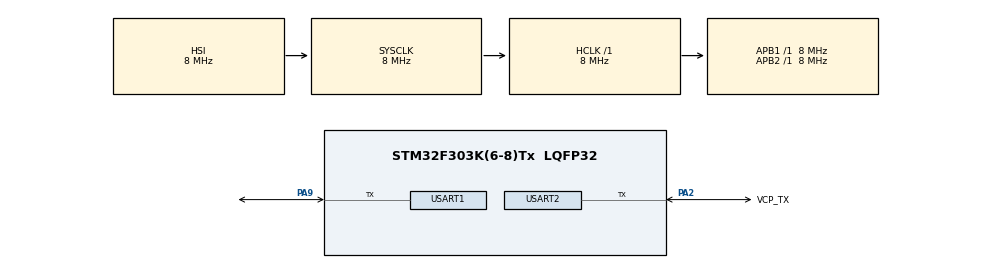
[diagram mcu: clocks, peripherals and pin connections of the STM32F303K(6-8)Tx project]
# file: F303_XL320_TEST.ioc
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Mcu.Family=STM32F3
Mcu.Name=STM32F303K(6-8)Tx
Mcu.Package=LQFP32
NVIC.PriorityGroup=NVIC_PRIORITYGROUP_4
PA13.GPIO_Label=SWDIO
PA13.Mode=Serial_Wire
PA13.Signal=SYS_JTMS-SWDIO
PA14.GPIO_Label=SWCLK
PA14.Mode=Serial_Wire
PA14.Signal=SYS_JTCK-SWCLK
PA15.GPIO_Label=VCP_RX
PA15.Signal=USART2_RX
PA2.GPIO_Label=VCP_TX
PA2.Mode=Half_duplex(single_wire_mode)
PA2.Signal=USART2_TX
PA9.GPIO_ModeDefaultOD=GPIO_MODE_AF_OD
PA9.GPIO_ModeDefaultPP=GPIO_MODE_AF_PP
PA9.GPIO_PuPd=GPIO_NOPULL
PA9.Mode=Half_duplex(single_wire_mode)
PA9.Signal=USART1_TX
PF0\ /\ OSC_IN.GPIO_Label=MCO
PF0\ /\ OSC_IN.Mode=HSE-External-Clock-Source
PF0\ /\ OSC_IN.Signal=RCC_OSC_IN
ProjectManager.HeapSize=0x200
ProjectManager.StackSize=0x400
ProjectManager.TargetToolchain=STM32CubeIDE
RCC.AHBFreq_Value=8000000
RCC.APB1Freq_Value=8000000
RCC.APB2Freq_Value=8000000
RCC.CortexFreq_Value=8000000
RCC.HSE_VALUE=8000000
RCC.HSI_VALUE=8000000
RCC.SYSCLKFreq_VALUE=8000000
USART1.BaudRate=100000
USART1.Mode=MODE_TX_RX
USART1.VirtualMode-Half_duplex(single_wire_mode)=VM_ASYNC
USART2.BaudRate=115200
USART2.VirtualMode-Half_duplex(single_wire_mode)=VM_ASYNC
board=NUCLEO-F303K8

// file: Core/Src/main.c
/* USER CODE BEGIN Header */
/**
  ******************************************************************************
  * @file           : main.c
  * @brief          : Main program body
  ******************************************************************************
  * @attention
  *
  * Copyright (c) 2024 STMicroelectronics.
  * All rights reserved.
  *
  * This software is licensed under terms that can be found in the LICENSE file
  * in the root directory of this software component.
  * If no LICENSE file comes with this software, it is provided AS-IS.
  *
  ******************************************************************************
  */
/* USER CODE END Header */
#include "main.h"
#include "usart.h"
#include "gpio.h"

/* USER CODE BEGIN Includes */
#include "XL320.h"
/* USER CODE END Includes */

void SystemClock_Config(void);

int main(void)
{

  /* MCU Configuration--------------------------------------------------------*/

  /* Reset of all peripherals, Initializes the Flash interface and the Systick. */
  HAL_Init();

  /* Configure the system clock */
  SystemClock_Config();

  /* Initialize all configured peripherals */
  MX_GPIO_Init();
  MX_USART2_UART_Init();
  MX_USART1_UART_Init();
  /* USER CODE BEGIN 2 */

  //XL320 xl320;
  //XL320_Init(&xl320, &huart2, 1, BR_115200);
  //XL320_EnableLED(&xl320, GREEN);
  uint8_t command[10] = {0xFF, 0xFF, 0xFD, 0x00, 0xFE, 0x03, 0x00, 0x01, 0x00, 0x00};
  uint8_t response[14] = {0};
  uint8_t found_id = 0;

  update_crc2(command, 8);
  HAL_HalfDuplex_EnableTransmitter(&huart1);
  HAL_UART_Transmit(&huart1, command, 10, 1000);

  HAL_HalfDuplex_EnableReceiver(&huart1);

  HAL_UART_Receive(&huart1, response, 14, 40);

  if(response[0] == 0xFF){
	  found_id = response[4];
  }
  /* USER CODE END 2 */

  /* Infinite loop */
  /* USER CODE BEGIN WHILE */
  while (1)
  {
	  //XL320_sendData(&xl320, SIZE_PING, XL320_Ping, 0);
	  //HAL_UART_Transmit(&huart2, (unsigned char *)"hello\n", sizeof("hello\n"), 500); //Debug

	  //HAL_Delay(1000);

    /* USER CODE END WHILE */

  }
}

void SystemClock_Config(void)
{
  RCC_OscInitTypeDef RCC_OscInitStruct = {0};
  RCC_ClkInitTypeDef RCC_ClkInitStruct = {0};
  RCC_PeriphCLKInitTypeDef PeriphClkInit = {0};

  /** Initializes the RCC Oscillators according to the specified parameters
  * in the RCC_OscInitTypeDef structure.
  */
  RCC_OscInitStruct.OscillatorType = RCC_OSCILLATORTYPE_HSI;
  RCC_OscInitStruct.HSIState = RCC_HSI_ON;
  RCC_OscInitStruct.HSICalibrationValue = RCC_HSICALIBRATION_DEFAULT;
  RCC_OscInitStruct.PLL.PLLState = RCC_PLL_NONE;
  if (HAL_RCC_OscConfig(&RCC_OscInitStruct) != HAL_OK)
  {
    Error_Handler();
  }

  /** Initializes the CPU, AHB and APB buses clocks
  */
  RCC_ClkInitStruct.ClockType = RCC_CLOCKTYPE_HCLK|RCC_CLOCKTYPE_SYSCLK
                              |RCC_CLOCKTYPE_PCLK1|RCC_CLOCKTYPE_PCLK2;
  RCC_ClkInitStruct.SYSCLKSource = RCC_SYSCLKSOURCE_HSI;
  RCC_ClkInitStruct.AHBCLKDivider = RCC_SYSCLK_DIV1;
  RCC_ClkInitStruct.APB1CLKDivider = RCC_HCLK_DIV1;
  RCC_ClkInitStruct.APB2CLKDivider = RCC_HCLK_DIV1;

  if (HAL_RCC_ClockConfig(&RCC_ClkInitStruct, FLASH_LATENCY_0) != HAL_OK)
  {
    Error_Handler();
  }
  PeriphClkInit.PeriphClockSelection = RCC_PERIPHCLK_USART1;
  PeriphClkInit.Usart1ClockSelection = RCC_USART1CLKSOURCE_PCLK1;
  if (HAL_RCCEx_PeriphCLKConfig(&PeriphClkInit) != HAL_OK)
  {
    Error_Handler();
  }
}

void Error_Handler(void)
{
  __disable_irq();
  while (1)
  {
  }
}
